# 8BIT_TIMER_COUNTER_1 register map
Vendor: Texas Instruments
Peripheral module from a debugger description file (folder msp430).
Registers are 8-bit, access not given, no defined reset value unless marked. A register's access mark holds for its fields unless they carry their own. Offsets are as the file gives them; lines under a group give offsets from that group; [hi:lo] are bit positions; {n}, {i} and the like mark numbered series; 'fields as' and 'values as' point back to an identical list; <NAME> marks a mode.

## 8BIT_TIMER/COUNTER
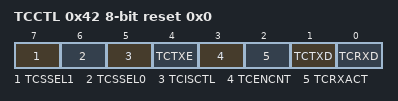
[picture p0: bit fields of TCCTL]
0x42 TCCTL rw reset 0x0 — Timer/Counter Control
  [7] TCSSEL1, [6] TCSSEL0, [5] TCISCTL, [4] TCTXE, [3] TCENCNT, [2] TCRXACT, [1] TCTXD, [0] TCRXD
0x43 TCPLD — Timer/Counter Preload
0x44 TCDAT — Timer/Counter Data
